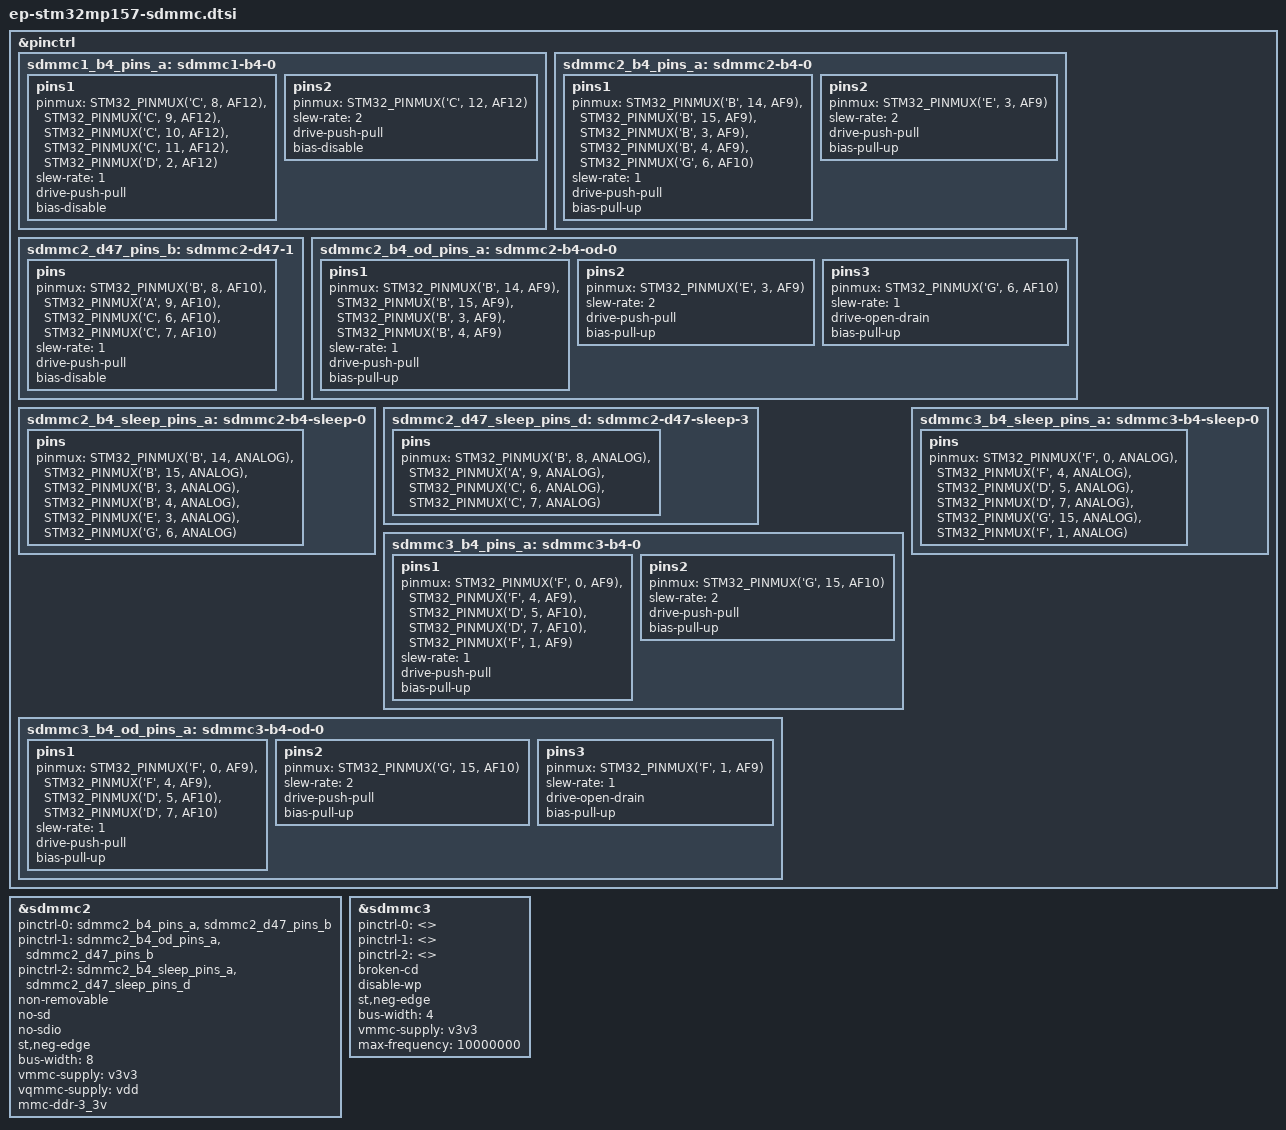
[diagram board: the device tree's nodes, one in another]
// SPDX-License-Identifier: (GPL-2.0+ OR BSD-3-Clause)
/*
 * Copyright (C) STMicroelectronics 2017 - All Rights Reserved
 * Author: Ludovic Barre <ludovic.barre@st.com> for STMicroelectronics.
 */
#include <dt-bindings/pinctrl/stm32-pinfunc.h>

&pinctrl {
	sdmmc1_b4_pins_a: sdmmc1-b4-0 {
		pins1 {
			pinmux = <STM32_PINMUX('C', 8, AF12)>, /* SDMMC1_D0 */
				 <STM32_PINMUX('C', 9, AF12)>, /* SDMMC1_D1 */
				 <STM32_PINMUX('C', 10, AF12)>, /* SDMMC1_D2 */
				 <STM32_PINMUX('C', 11, AF12)>, /* SDMMC1_D3 */
				 <STM32_PINMUX('D', 2, AF12)>; /* SDMMC1_CMD */
			slew-rate = <1>;
			drive-push-pull;
			bias-disable;
		};
		pins2 {
			pinmux = <STM32_PINMUX('C', 12, AF12)>; /* SDMMC1_CK */
			slew-rate = <2>;
			drive-push-pull;
			bias-disable;
		};
	};	
		
	sdmmc2_b4_pins_a: sdmmc2-b4-0 {
		pins1 {
			pinmux = <STM32_PINMUX('B', 14, AF9)>, /* SDMMC2_D0 */
				 <STM32_PINMUX('B', 15, AF9)>, /* SDMMC2_D1 */
				 <STM32_PINMUX('B', 3, AF9)>, /* SDMMC2_D2 */
				 <STM32_PINMUX('B', 4, AF9)>, /* SDMMC2_D3 */
				 <STM32_PINMUX('G', 6, AF10)>; /* SDMMC2_CMD */
			slew-rate = <1>;
			drive-push-pull;
			bias-pull-up;
		};
		pins2 {
			pinmux = <STM32_PINMUX('E', 3, AF9)>; /* SDMMC2_CK */
			slew-rate = <2>;
			drive-push-pull;
			bias-pull-up;
		};
	};
	
	sdmmc2_d47_pins_b: sdmmc2-d47-1 {
		pins {
			pinmux = <STM32_PINMUX('B', 8, AF10)>,  /* SDMMC2_D4 */
				 <STM32_PINMUX('A', 9, AF10)>, /* SDMMC2_D5 */
				 <STM32_PINMUX('C', 6, AF10)>, /* SDMMC2_D6 */
				 <STM32_PINMUX('C', 7, AF10)>; /* SDMMC2_D7 */
			slew-rate = <1>;
			drive-push-pull;
			bias-disable;
		};
	};
	
	sdmmc2_b4_od_pins_a: sdmmc2-b4-od-0 {
		pins1 {
			pinmux = <STM32_PINMUX('B', 14, AF9)>, /* SDMMC2_D0 */
				 <STM32_PINMUX('B', 15, AF9)>, /* SDMMC2_D1 */
				 <STM32_PINMUX('B', 3, AF9)>, /* SDMMC2_D2 */
				 <STM32_PINMUX('B', 4, AF9)>; /* SDMMC2_D3 */
			slew-rate = <1>;
			drive-push-pull;
			bias-pull-up;
		};
		pins2 {
			pinmux = <STM32_PINMUX('E', 3, AF9)>; /* SDMMC2_CK */
			slew-rate = <2>;
			drive-push-pull;
			bias-pull-up;
		};
		pins3 {
			pinmux = <STM32_PINMUX('G', 6, AF10)>; /* SDMMC2_CMD */
			slew-rate = <1>;
			drive-open-drain;
			bias-pull-up;
		};
	};
	
	sdmmc2_b4_sleep_pins_a: sdmmc2-b4-sleep-0 {
		pins {
			pinmux = <STM32_PINMUX('B', 14, ANALOG)>, /* SDMMC2_D0 */
				 <STM32_PINMUX('B', 15, ANALOG)>, /* SDMMC2_D1 */
				 <STM32_PINMUX('B', 3, ANALOG)>, /* SDMMC2_D2 */
				 <STM32_PINMUX('B', 4, ANALOG)>, /* SDMMC2_D3 */
				 <STM32_PINMUX('E', 3, ANALOG)>, /* SDMMC2_CK */
				 <STM32_PINMUX('G', 6, ANALOG)>; /* SDMMC2_CMD */
		};
	};
	
	sdmmc2_d47_sleep_pins_d: sdmmc2-d47-sleep-3 {
		pins {
			pinmux = <STM32_PINMUX('B', 8, ANALOG)>, /* SDMMC2_D4 */
				 <STM32_PINMUX('A', 9, ANALOG)>, /* SDMMC2_D5 */
				 <STM32_PINMUX('C', 6, ANALOG)>, /* SDMMC2_D6 */
				 <STM32_PINMUX('C', 7, ANALOG)>; /* SDMMC2_D7 */
		};
	};
	
	sdmmc3_b4_pins_a: sdmmc3-b4-0 {
		pins1 {
			pinmux = <STM32_PINMUX('F', 0, AF9)>, /* SDMMC3_D0 */
				 <STM32_PINMUX('F', 4, AF9)>, /* SDMMC3_D1 */
				 <STM32_PINMUX('D', 5, AF10)>, /* SDMMC3_D2 */
				 <STM32_PINMUX('D', 7, AF10)>, /* SDMMC3_D3 */
				 <STM32_PINMUX('F', 1, AF9)>; /* SDMMC3_CMD */
			slew-rate = <1>;
			drive-push-pull;
			bias-pull-up;
		};
		pins2 {
			pinmux = <STM32_PINMUX('G', 15, AF10)>; /* SDMMC3_CK */
			slew-rate = <2>;
			drive-push-pull;
			bias-pull-up;
		};
	};

	sdmmc3_b4_od_pins_a: sdmmc3-b4-od-0 {
		pins1 {
			pinmux = <STM32_PINMUX('F', 0, AF9)>, /* SDMMC3_D0 */
				 <STM32_PINMUX('F', 4, AF9)>, /* SDMMC3_D1 */
				<STM32_PINMUX('D', 5, AF10)>, /* SDMMC3_D2 */
				 <STM32_PINMUX('D', 7, AF10)>; /* SDMMC3_D3 */
			slew-rate = <1>;
			drive-push-pull;
			bias-pull-up;
		};
		pins2 {
			pinmux = <STM32_PINMUX('G', 15, AF10)>; /* SDMMC3_CK */
			slew-rate = <2>;
			drive-push-pull;
			bias-pull-up;
		};
		pins3 {
			pinmux = <STM32_PINMUX('F', 1, AF9)>; /* SDMMC2_CMD */
			slew-rate = <1>;
			drive-open-drain;
			bias-pull-up;
		};
	};

	sdmmc3_b4_sleep_pins_a: sdmmc3-b4-sleep-0 {
		pins {
			pinmux = <STM32_PINMUX('F', 0, ANALOG)>, /* SDMMC3_D0 */
				 <STM32_PINMUX('F', 4, ANALOG)>, /* SDMMC3_D1 */
				 <STM32_PINMUX('D', 5, ANALOG)>, /* SDMMC3_D2 */
				 <STM32_PINMUX('D', 7, ANALOG)>, /* SDMMC3_D3 */
				 <STM32_PINMUX('G', 15, ANALOG)>, /* SDMMC3_CK */
				 <STM32_PINMUX('F', 1, ANALOG)>; /* SDMMC3_CMD */
		};
	};
	
	
	
	
};

&sdmmc2 {
	pinctrl-names = "default", "opendrain", "sleep";
	pinctrl-0 = <&sdmmc2_b4_pins_a &sdmmc2_d47_pins_b>;
	pinctrl-1 = <&sdmmc2_b4_od_pins_a &sdmmc2_d47_pins_b>;
	pinctrl-2 = <&sdmmc2_b4_sleep_pins_a &sdmmc2_d47_sleep_pins_d>;
	non-removable;
	no-sd;
	no-sdio;
	st,neg-edge;
	bus-width = <8>;
	vmmc-supply = <&v3v3>;
	vqmmc-supply = <&vdd>;
	mmc-ddr-3_3v;
	status = "okay";
};

&sdmmc3 {
	pinctrl-names = "default", "opendrain", "sleep";
	pinctrl-0 = <>;
	pinctrl-1 = <>;
	pinctrl-2 = <>;
	broken-cd;
	disable-wp;
	st,neg-edge;
	bus-width = <4>;
	vmmc-supply = <&v3v3>;
	max-frequency = <10000000>;
	status = "okay";
};
